# R7FA2A2AD register map
Vendor: Renesas Electronics Corporation; Series: RA2A2; File version: 1.20.02
CPU: CM23 r1p0, little endian, MPU, no FPU, VTOR, 2 interrupt priority bits, 32 interrupts
Registers are 8-bit, read-write, reset 0x0 unless marked. A register's access mark holds for its fields unless they carry their own. Offsets are from the block's base; [hi:lo] are bit positions; {n}, {i} and the like mark numbered series; 'fields as' and 'values as' point back to an identical list.

## RTC — Realtime Clock
Base 0x40044000
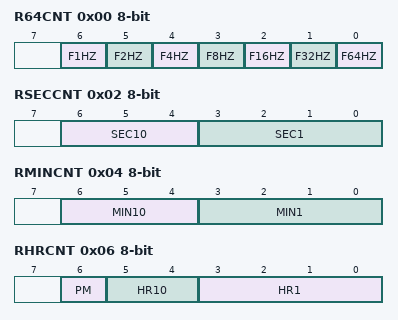
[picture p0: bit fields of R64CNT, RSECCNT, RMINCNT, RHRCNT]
0x00 R64CNT ro (reset mask 0x80) — 64-Hz Counter
  [6] F1HZ — 1-Hz Flag
  [5] F2HZ — 2-Hz Flag
  [4] F4HZ — 4-Hz Flag
  [3] F8HZ — 8-Hz Flag
  [2] F16HZ — 16-Hz Flag
  [1] F32HZ — 32-Hz Flag
  [0] F64HZ — 64-Hz Flag
{0x2+2i} BCNT{i} (i=0..3) reset not defined — Binary Counter {i}
  [7:0] BCNT — Binary Counter
0x02 RSECCNT reset not defined — Second Counter (in Calendar Count Mode)
  [6:4] SEC10 — 10-Second Count
  [3:0] SEC1 — 1-Second Count
0x04 RMINCNT reset not defined — Minute Counter (in Calendar Count Mode)
  [6:4] MIN10 — 10-Minute Count
  [3:0] MIN1 — 1-Minute Count
0x06 RHRCNT reset not defined — Hour Counter (in Calendar Count Mode)
  [6] PM — AM/PM select for time counter setting.
    0=AM; 1=PM
  [5:4] HR10 — 10-Hour Count
  [3:0] HR1 — 1-Hour Count
0x08 RWKCNT reset not defined — Day-of-Week Counter (in Calendar Count Mode)
  [2:0] DAYW — Day-of-Week Counting
    0=Sunday; 1=Monday; 2=Tuesday; 3=Wednesday; 4=Thursday; 5=Friday; 6=Saturday; 7=Setting prohibited
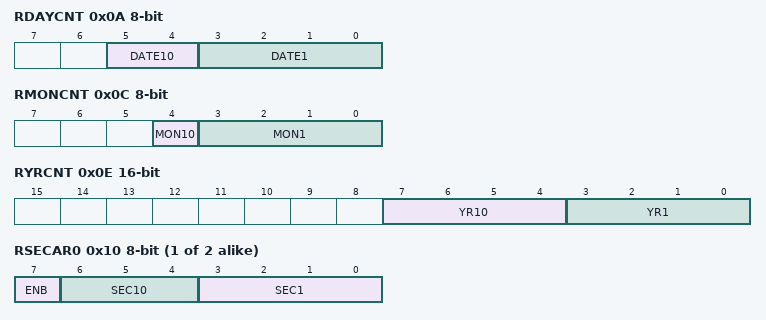
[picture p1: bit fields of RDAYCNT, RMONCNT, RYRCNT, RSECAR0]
0x0A RDAYCNT (reset mask 0xC0) — Day Counter
  [5:4] DATE10 — 10-Day Count
  [3:0] DATE1 — 1-Day Count
0x0C RMONCNT (reset mask 0xE0) — Month Counter
  [4] MON10 — 10-Month Count
  [3:0] MON1 — 1-Month Count
0x0E RYRCNT 16-bit (reset mask 0xFF00) — Year Counter
  [7:4] YR10 — 10-Year Count
  [3:0] YR1 — 1-Year Count
{0x10+0x20*i} BCNT0AR{i} (i=0..1) reset not defined — Binary Counter 0 Alarm Register {i}
  [7:0] BCNTAR — Alarm register associated with the 32-bit binary counter
{0x10+0x20*i} RSECAR{i} (i=0..1) reset not defined (alternate view of BCNT0AR{i}) — Second Alarm Register {i}
  [7] ENB
    0=Do not compare register value with RSECCNT counter value; 1=Compare register value with RSECCNT counter value
  [6:4] SEC10 — 10 Seconds
  [3:0] SEC1 — 1 Second
{0x12+0x20*i} BCNT1AR{i} (i=0..1) reset not defined — Binary Counter 1 Alarm Register {i}
  fields as BCNT0AR0
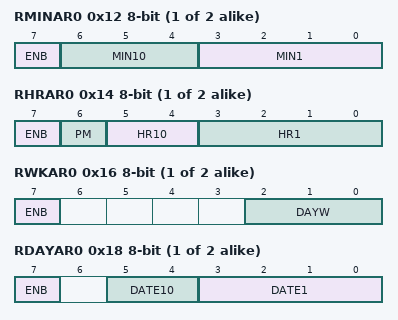
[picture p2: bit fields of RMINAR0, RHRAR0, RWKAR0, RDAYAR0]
{0x12+0x20*i} RMINAR{i} (i=0..1) reset not defined (alternate view of BCNT1AR{i}) — Minute Alarm Register {i}
  [7] ENB
    0=Do not compare register value with RMINCNT counter value; 1=Compare register value with RMINCNT counter value
  [6:4] MIN10 — 10 Minutes
  [3:0] MIN1 — 1 Minute
{0x14+0x20*i} BCNT2AR{i} (i=0..1) reset not defined — Binary Counter 2 Alarm Register {i}
  fields as BCNT0AR0
{0x14+0x20*i} RHRAR{i} (i=0..1) reset not defined (alternate view of BCNT2AR{i}) — Hour Alarm Register {i}
  [7] ENB
    0=Do not compare register value with RHRCNT counter value; 1=Compare register value with RHRCNT counter value
  [6] PM — AM/PM select for alarm setting.
    0=AM; 1=PM
  [5:4] HR10 — 10 Hours
  [3:0] HR1 — 1 Hour
{0x16+0x20*i} BCNT3AR{i} (i=0..1) reset not defined — Binary Counter 3 Alarm Register {i}
  fields as BCNT0AR0
{0x16+0x20*i} RWKAR{i} (i=0..1) reset not defined (alternate view of BCNT3AR{i}) — Day of Week Alarm Register {i}
  [7] ENB
    0=Do not compare register value with RWKCNT counter value; 1=Compare register value with RWKCNT counter value
  [2:0] DAYW — Day-of-Week Setting
    values as RWKCNT.DAYW
{0x18+0x20*i} BCNT0AER{i} (i=0..1) reset not defined — Binary Counter m Alarm Enable Register {i}
  [7:0] ENB — Setting the alarm enable associated with the 32-bit binary counter
{0x18+0x20*i} RDAYAR{i} (i=0..1) reset not defined (alternate view of BCNT0AER{i}) — Date Alarm Register {i}
  [7] ENB
    0=Do not compare register value with RDAYCNT counter value; 1=Compare register value with RDAYCNT counter value
  [5:4] DATE10 — 10 Days
  [3:0] DATE1 — 1 Day
{0x1A+0x20*i} BCNT1AER{i} (i=0..1) reset not defined — Binary Counter m Alarm Enable Register {i}
  fields as BCNT0AER0
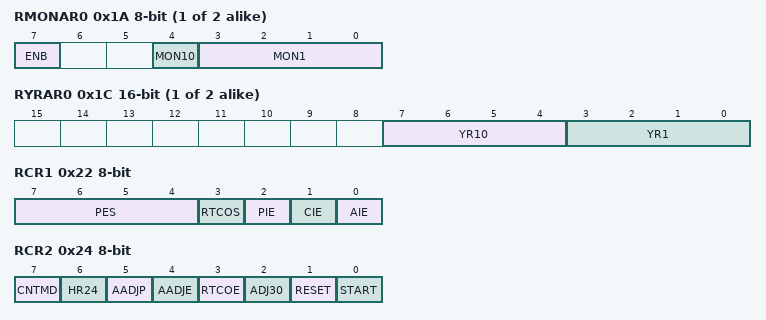
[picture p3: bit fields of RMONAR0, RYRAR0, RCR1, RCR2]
{0x1A+0x20*i} RMONAR{i} (i=0..1) reset not defined (alternate view of BCNT1AER{i}) — Month Alarm Register {i}
  [7] ENB
    0=Do not compare register value with RMONCNT counter value; 1=Compare register value with RMONCNT counter value
  [4] MON10 — 10 Months
  [3:0] MON1 — 1 Month
{0x1C+0x20*i} BCNT2AER{i} (i=0..1) 16-bit (reset mask 0xFF00) — Binary Counter 2 Alarm Enable Register {i}
  fields as BCNT0AER0
{0x1C+0x20*i} RYRAR{i} (i=0..1) 16-bit (reset mask 0xFF00) (alternate view of BCNT2AER{i}) — Year Alarm Register {i}
  [7:4] YR10 — 10 Years
  [3:0] YR1 — 1 Year
{0x1E+0x20*i} BCNT3AER{i} (i=0..1) reset not defined — Binary Counter 3 Alarm Enable Register {i}
  fields as BCNT0AER0
{0x1E+0x20*i} RYRAREN{i} (i=0..1) reset not defined (alternate view of BCNT3AER{i}) — Year Alarm Enable Register {i}
  [7] ENB
    0=Do not compare register value with the RYRCNT counter value; 1=Compare register value with the RYRCNT counter value
0x22 RCR1 (reset mask 0xA) — RTC Control Register 1
  [7:4] PES — Periodic Interrupt Select
    6=Generate periodic interrupt every 1/256 second; 7=Generate periodic interrupt every 1/128 second; 8=Generate periodic interrupt every 1/64 second; 9=Generate periodic interrupt every 1/32 second; 10=Generate periodic interrupt every 1/16 second; 11=Generate periodic interrupt every 1/8 second; 12=Generate periodic interrupt every 1/4 second; 13=Generate periodic interrupt every 1/2 second; 14=Generate periodic interrupt every 1 second; 15=Generate periodic interrupt every 2 seconds; other=Others (Do not generate periodic interrupts)
  [3] RTCOS — RTCOUT Output Select
    0=Outputs 1 Hz on RTCOUT; 1=Outputs 64 Hz RTCOUT
  [2] PIE — Periodic Interrupt Enable
    0=Disable periodic interrupt requests; 1=Enable periodic interrupt requests
  [1] CIE — Carry Interrupt Enable
    0=Disable carry interrupt requests; 1=Enable carry interrupt requests
  [0] AIE — Alarm Interrupt Enable
    0=Disable alarm interrupt requests; 1=Enable alarm interrupt requests
0x24 RCR2 (reset mask 0xE) — RTC Control Register 2 (in Calendar Count Mode)
  [7] CNTMD — Count Mode Select
    0=Calendar count mode; 1=Binary count mode
  [6] HR24 — Hours Mode
    0=Operate RTC in 12-hour mode; 1=Operate RTC in 24-hour mode
  [5] AADJP — Automatic Adjustment Period Select
    0=The RADJ.ADJ[5:0] setting value is adjusted from the count value of the prescaler every minute; 1=The RADJ.ADJ[5:0] setting value is adjusted from the count value of the prescaler every 10 seconds
  [4] AADJE — Automatic Adjustment Enable
    0=Disable automatic adjustment; 1=Enable automatic adjustment
  [3] RTCOE — RTCOUT Output Enable
    0=Disable RTCOUT output; 1=Enable RTCOUT output
  [2] ADJ30 — 30-Second Adjustment
    0=In writing: Invalid (writing 0 has no effect). In reading: Normal time operation in progress, or 30-second adjustment has completed.; 1=In writing: Execute 30-second adjustment. In reading: 30-second adjustment in progress.
  [1] RESET — RTC Software Reset
    0=In writing: Invalid (writing 0 has no effect). In reading: Normal time operation in progress, or an RTC software reset has completed.; 1=In writing: Initialize the prescaler and target registers for RTC software reset. In reading: RTC software reset in progress.
  [0] START
    0=Stop prescaler and time counter; 1=Operate prescaler and time counter normally
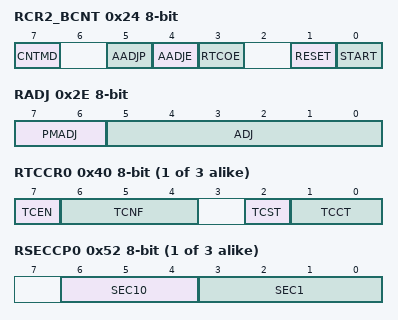
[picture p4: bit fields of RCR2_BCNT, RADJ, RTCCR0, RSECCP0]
0x24 RCR2_BCNT (reset mask 0xE) (alternate view of RCR2) — RTC Control Register 2 (in Binary Count Mode)
  [7] CNTMD — Count Mode Select
    0=Calendar count mode; 1=Binary count mode
  [5] AADJP — Automatic Adjustment Period Select
    0=Add or subtract RADJ.ADJ[5:0] bits from prescaler count value every 32 seconds; 1=Add or subtract RADJ.ADJ[5:0] bits from prescaler count value every 8 seconds
  [4] AADJE — Automatic Adjustment Enable
    values as RCR2.AADJE
  [3] RTCOE — RTCOUT Output Enable
    0=Disable RTCOUT output; 1=Enable RTCOUT output
  [1] RESET — RTC Software Reset
    values as RCR2.RESET
  [0] START
    0=Stop the 32-bit binary counter, 64-Hz counter, and prescaler; 1=Operate the 32-bit binary counter, 64-Hz counter, and prescaler normally
0x28 RCR4 — RTC Control Register 4
  [0] ADJ500M — 0.5-second adjustment
    0=In writing: Invalid (writing 0 has no effect) In reading: Normal time operation in progress, or 0.5-second adjustment has completed; 1=In writing: Execute 0.5-second adjustment In reading: 0.5-second adjustment in progress
0x2E RADJ reset not defined — Time Error Adjustment Register
  [7:6] PMADJ — Plus-Minus
    0=Do not perform adjustment; 1=Adjustment is performed by the addition to the prescaler; 2=Adjustment is performed by the subtraction from the prescaler; 3=Setting prohibited
  [5:0] ADJ — Adjustment Value
{0x40+2i} RTCCR{i} (i=0..2) (reset mask 0x8) — Time Capture Control Register {i}
  [7] TCEN — Time Capture Event Input Pin Enable
    0=Disable the RTCICn pin as the time capture event input pin; 1=Enable the RTCICn pin as the time capture event input pin
  [6:4] TCNF — Time Capture Noise Filter Control
    0=Turn noise filter off; 1=Setting prohibited; 2=Turn noise filter on (count source); 3=Turn noise filter on (count source by divided by 32); 4=Turn noise filter on (count source by divided by 4096); 5=Turn noise filter on (count source by divided by 8192); other=Others (Setting prohibited)
  [2] TCST — Time Capture Status
    0=No event detected; 1=Event detected
  [1:0] TCCT — Time Capture Control
    0=Do not detect events; 1=Detect rising edge; 2=Detect falling edge; 3=Detect both edges
{0x52+0x10*i} BCNT0CP{i} (i=0..2) ro reset not defined — BCNT0 Capture Register {i}
{0x52+0x10*i} RSECCP{i} (i=0..2) ro reset not defined (alternate view of BCNT0CP{i}) — Second Capture Register {i}
  [6:4] SEC10 — 10-Second Capture
  [3:0] SEC1 — 1-Second Capture
{0x54+0x10*i} BCNT1CP{i} (i=0..2) ro reset not defined — BCNT1 Capture Register {i}
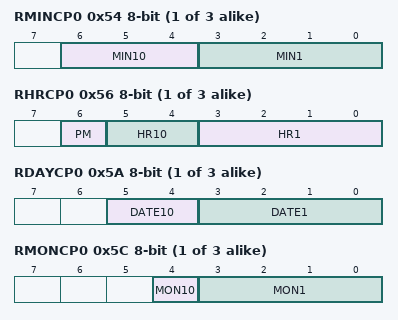
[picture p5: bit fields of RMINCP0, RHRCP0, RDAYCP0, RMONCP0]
{0x54+0x10*i} RMINCP{i} (i=0..2) ro reset not defined (alternate view of BCNT1CP{i}) — Minute Capture Register {i}
  [6:4] MIN10 — 10-Minute Capture
  [3:0] MIN1 — 1-Minute Capture
{0x56+0x10*i} BCNT2CP{i} (i=0..2) ro reset not defined — BCNT2 Capture Register {i}
{0x56+0x10*i} RHRCP{i} (i=0..2) ro reset not defined (alternate view of BCNT2CP{i}) — Hour Capture Register {i}
  [6] PM
    0=AM; 1=PM
  [5:4] HR10 — 10-Hour Capture
  [3:0] HR1 — 1-Hour Capture
{0x5A+0x10*i} BCNT3CP{i} (i=0..2) ro reset not defined — BCNT3 Capture Register {i}
{0x5A+0x10*i} RDAYCP{i} (i=0..2) ro reset not defined (alternate view of BCNT3CP{i}) — Date Capture Register {i}
  [5:4] DATE10 — 10-Day Capture
  [3:0] DATE1 — 1-Day Capture
{0x5C+0x10*i} RMONCP{i} (i=0..2) ro (reset mask 0xE0) — Month Capture Register {i}
  [4] MON10 — 10-Month Capture
  [3:0] MON1 — 1-Month Capture
